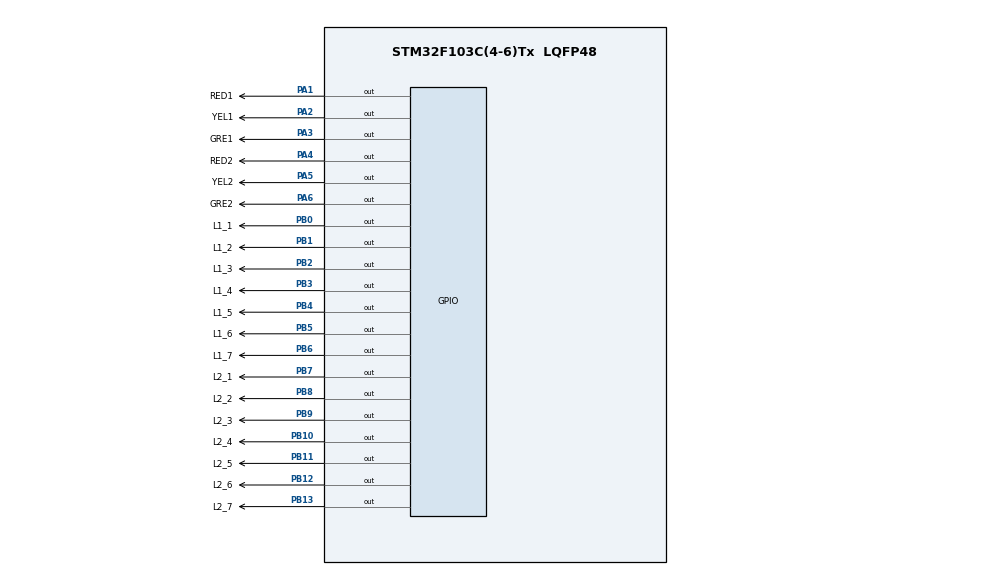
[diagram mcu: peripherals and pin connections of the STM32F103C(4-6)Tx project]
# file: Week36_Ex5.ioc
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Mcu.Family=STM32F1
PD1-OSC_OUT.Mode=HSE-External-Oscillator
PB9.GPIO_Label=L2_3
PB11.GPIO_Label=L2_5
PA6.GPIO_Label=GRE2
PB0.GPIO_Label=L1_1
PB6.GPIO_Label=L1_7
PD0-OSC_IN.Signal=RCC_OSC_IN
PB13.GPIO_Label=L2_7
PB11.Signal=GPIO_Output
PB13.Signal=GPIO_Output
VP_SYS_VS_ND.Mode=No_Debug
ProjectManager.StackSize=0x400
PD1-OSC_OUT.Signal=RCC_OSC_OUT
PB8.GPIO_Label=L2_2
ProjectManager.TargetToolchain=STM32CubeIDE
PB10.GPIO_Label=L2_4
PB6.Signal=GPIO_Output
PA1.Signal=GPIO_Output
PD0-OSC_IN.Mode=HSE-External-Oscillator
PB10.Signal=GPIO_Output
PA5.Signal=GPIO_Output
PB2.Signal=GPIO_Output
board=custom
PB12.GPIO_Label=L2_6
RCC.APB2Freq_Value=8000000
PB4.GPIO_Label=L1_5
PB1.GPIO_Label=L1_2
PA1.GPIO_Label=RED1
PB7.Signal=GPIO_Output
Mcu.Name=STM32F103C(4-6)Tx
PA2.Signal=GPIO_Output
PB7.GPIO_Label=L2_1
PB3.Signal=GPIO_Output
PA4.Signal=GPIO_Output
Mcu.Package=LQFP48
PB5.Signal=GPIO_Output
PB9.Signal=GPIO_Output
PA6.Signal=GPIO_Output
PB1.Signal=GPIO_Output
PA5.GPIO_Label=YEL2
PA2.GPIO_Label=YEL1
PB2.GPIO_Label=L1_3
ProjectManager.HeapSize=0x200
NVIC.PriorityGroup=NVIC_PRIORITYGROUP_4
PB5.GPIO_Label=L1_6
PB8.Signal=GPIO_Output
RCC.APB1Freq_Value=8000000
PB0.Signal=GPIO_Output
PA4.GPIO_Label=RED2
PB12.Signal=GPIO_Output
PB4.Signal=GPIO_Output
PA3.GPIO_Label=GRE1
PA3.Signal=GPIO_Output
PB3.GPIO_Label=L1_4

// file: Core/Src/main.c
/* USER CODE BEGIN Header */
/**
  ******************************************************************************
  * @file           : main.c
  * @brief          : Main program body
  ******************************************************************************
  * @attention
  *
  * <h2><center>&copy; Copyright (c) 2021 STMicroelectronics.
  * All rights reserved.</center></h2>
  *
  * This software component is licensed by ST under BSD 3-Clause license,
  * the "License"; You may not use this file except in compliance with the
  * License. You may obtain a copy of the License at:
  *                        opensource.org/licenses/BSD-3-Clause
  *
  ******************************************************************************
  */
/* USER CODE END Header */
#include "main.h"

void SystemClock_Config(void);
static void MX_GPIO_Init(void);
void display7SEG(int num)
{

	HAL_GPIO_WritePin(GPIOB, GPIO_PIN_0, GPIO_PIN_SET);
	HAL_GPIO_WritePin(GPIOB, GPIO_PIN_1, GPIO_PIN_SET);
	HAL_GPIO_WritePin(GPIOB, GPIO_PIN_2, GPIO_PIN_SET);
	HAL_GPIO_WritePin(GPIOB, GPIO_PIN_3, GPIO_PIN_SET);
	HAL_GPIO_WritePin(GPIOB, GPIO_PIN_4, GPIO_PIN_SET);
	HAL_GPIO_WritePin(GPIOB, GPIO_PIN_5, GPIO_PIN_SET);
	HAL_GPIO_WritePin(GPIOB, GPIO_PIN_6, GPIO_PIN_SET);
	switch (num) {
		case 0:
			HAL_GPIO_WritePin(GPIOB, GPIO_PIN_0, GPIO_PIN_RESET);
			HAL_GPIO_WritePin(GPIOB, GPIO_PIN_1, GPIO_PIN_RESET);
			HAL_GPIO_WritePin(GPIOB, GPIO_PIN_2, GPIO_PIN_RESET);
			HAL_GPIO_WritePin(GPIOB, GPIO_PIN_3, GPIO_PIN_RESET);
			HAL_GPIO_WritePin(GPIOB, GPIO_PIN_4, GPIO_PIN_RESET);
			HAL_GPIO_WritePin(GPIOB, GPIO_PIN_5, GPIO_PIN_RESET);
			break;
		case 1:
			HAL_GPIO_WritePin(GPIOB, GPIO_PIN_1, GPIO_PIN_RESET);
			HAL_GPIO_WritePin(GPIOB, GPIO_PIN_2, GPIO_PIN_RESET);
			break;
		case 2:
			HAL_GPIO_WritePin(GPIOB, GPIO_PIN_0, GPIO_PIN_RESET);
			HAL_GPIO_WritePin(GPIOB, GPIO_PIN_1, GPIO_PIN_RESET);
			HAL_GPIO_WritePin(GPIOB, GPIO_PIN_3, GPIO_PIN_RESET);
			HAL_GPIO_WritePin(GPIOB, GPIO_PIN_4, GPIO_PIN_RESET);
			HAL_GPIO_WritePin(GPIOB, GPIO_PIN_6, GPIO_PIN_RESET);
			break;
		case 3:
			HAL_GPIO_WritePin(GPIOB, GPIO_PIN_0, GPIO_PIN_RESET);
			HAL_GPIO_WritePin(GPIOB, GPIO_PIN_1, GPIO_PIN_RESET);
			HAL_GPIO_WritePin(GPIOB, GPIO_PIN_2, GPIO_PIN_RESET);
			HAL_GPIO_WritePin(GPIOB, GPIO_PIN_3, GPIO_PIN_RESET);
			HAL_GPIO_WritePin(GPIOB, GPIO_PIN_6, GPIO_PIN_RESET);
			break;
		case 4:
			HAL_GPIO_WritePin(GPIOB, GPIO_PIN_1, GPIO_PIN_RESET);
			HAL_GPIO_WritePin(GPIOB, GPIO_PIN_2, GPIO_PIN_RESET);
			HAL_GPIO_WritePin(GPIOB, GPIO_PIN_5, GPIO_PIN_RESET);
			HAL_GPIO_WritePin(GPIOB, GPIO_PIN_6, GPIO_PIN_RESET);
			break;
		case 5:
			HAL_GPIO_WritePin(GPIOB, GPIO_PIN_0, GPIO_PIN_RESET);
			HAL_GPIO_WritePin(GPIOB, GPIO_PIN_5, GPIO_PIN_RESET);
			HAL_GPIO_WritePin(GPIOB, GPIO_PIN_6, GPIO_PIN_RESET);
			HAL_GPIO_WritePin(GPIOB, GPIO_PIN_2, GPIO_PIN_RESET);
			HAL_GPIO_WritePin(GPIOB, GPIO_PIN_3, GPIO_PIN_RESET);
			break;
		case 6:
			HAL_GPIO_WritePin(GPIOB, GPIO_PIN_0, GPIO_PIN_RESET);
			HAL_GPIO_WritePin(GPIOB, GPIO_PIN_2, GPIO_PIN_RESET);
			HAL_GPIO_WritePin(GPIOB, GPIO_PIN_3, GPIO_PIN_RESET);
			HAL_GPIO_WritePin(GPIOB, GPIO_PIN_4, GPIO_PIN_RESET);
			HAL_GPIO_WritePin(GPIOB, GPIO_PIN_5, GPIO_PIN_RESET);
			HAL_GPIO_WritePin(GPIOB, GPIO_PIN_6, GPIO_PIN_RESET);
			break;
		case 7:
			HAL_GPIO_WritePin(GPIOB, GPIO_PIN_0, GPIO_PIN_RESET);
			HAL_GPIO_WritePin(GPIOB, GPIO_PIN_1, GPIO_PIN_RESET);
			HAL_GPIO_WritePin(GPIOB, GPIO_PIN_2, GPIO_PIN_RESET);
			break;
		case 8:
			HAL_GPIO_WritePin(GPIOB, GPIO_PIN_0, GPIO_PIN_RESET);
			HAL_GPIO_WritePin(GPIOB, GPIO_PIN_1, GPIO_PIN_RESET);
			HAL_GPIO_WritePin(GPIOB, GPIO_PIN_2, GPIO_PIN_RESET);
			HAL_GPIO_WritePin(GPIOB, GPIO_PIN_3, GPIO_PIN_RESET);
			HAL_GPIO_WritePin(GPIOB, GPIO_PIN_4, GPIO_PIN_RESET);
			HAL_GPIO_WritePin(GPIOB, GPIO_PIN_5, GPIO_PIN_RESET);
			HAL_GPIO_WritePin(GPIOB, GPIO_PIN_6, GPIO_PIN_RESET);

			break;
		case 9:
			HAL_GPIO_WritePin(GPIOB, GPIO_PIN_0, GPIO_PIN_RESET);
			HAL_GPIO_WritePin(GPIOB, GPIO_PIN_1, GPIO_PIN_RESET);
			HAL_GPIO_WritePin(GPIOB, GPIO_PIN_2, GPIO_PIN_RESET);
			HAL_GPIO_WritePin(GPIOB, GPIO_PIN_3, GPIO_PIN_RESET);
			HAL_GPIO_WritePin(GPIOB, GPIO_PIN_5, GPIO_PIN_RESET);
			HAL_GPIO_WritePin(GPIOB, GPIO_PIN_6, GPIO_PIN_RESET);
			break;
		default:
			HAL_GPIO_WritePin(GPIOB, GPIO_PIN_3, GPIO_PIN_SET);
			break;
		}
}

void display7SEG2(int num)
{

	HAL_GPIO_WritePin(GPIOB, GPIO_PIN_7, GPIO_PIN_SET);
	HAL_GPIO_WritePin(GPIOB, GPIO_PIN_8, GPIO_PIN_SET);
	HAL_GPIO_WritePin(GPIOB, GPIO_PIN_9, GPIO_PIN_SET);
	HAL_GPIO_WritePin(GPIOB, GPIO_PIN_10, GPIO_PIN_SET);
	HAL_GPIO_WritePin(GPIOB, GPIO_PIN_11, GPIO_PIN_SET);
	HAL_GPIO_WritePin(GPIOB, GPIO_PIN_12, GPIO_PIN_SET);
	HAL_GPIO_WritePin(GPIOB, GPIO_PIN_13, GPIO_PIN_SET);
	switch (num) {
		case 0:
			HAL_GPIO_WritePin(GPIOB, GPIO_PIN_7, GPIO_PIN_RESET);
			HAL_GPIO_WritePin(GPIOB, GPIO_PIN_8, GPIO_PIN_RESET);
			HAL_GPIO_WritePin(GPIOB, GPIO_PIN_9, GPIO_PIN_RESET);
			HAL_GPIO_WritePin(GPIOB, GPIO_PIN_10, GPIO_PIN_RESET);
			HAL_GPIO_WritePin(GPIOB, GPIO_PIN_11, GPIO_PIN_RESET);
			HAL_GPIO_WritePin(GPIOB, GPIO_PIN_12, GPIO_PIN_RESET);
			break;
		case 1:
			HAL_GPIO_WritePin(GPIOB, GPIO_PIN_8, GPIO_PIN_RESET);
			HAL_GPIO_WritePin(GPIOB, GPIO_PIN_9, GPIO_PIN_RESET);
			break;
		case 2:
			HAL_GPIO_WritePin(GPIOB, GPIO_PIN_7, GPIO_PIN_RESET);
			HAL_GPIO_WritePin(GPIOB, GPIO_PIN_8, GPIO_PIN_RESET);
			HAL_GPIO_WritePin(GPIOB, GPIO_PIN_10, GPIO_PIN_RESET);
			HAL_GPIO_WritePin(GPIOB, GPIO_PIN_11, GPIO_PIN_RESET);
			HAL_GPIO_WritePin(GPIOB, GPIO_PIN_13, GPIO_PIN_RESET);
			break;
		case 3:
			HAL_GPIO_WritePin(GPIOB, GPIO_PIN_7, GPIO_PIN_RESET);
			HAL_GPIO_WritePin(GPIOB, GPIO_PIN_8, GPIO_PIN_RESET);
			HAL_GPIO_WritePin(GPIOB, GPIO_PIN_9, GPIO_PIN_RESET);
			HAL_GPIO_WritePin(GPIOB, GPIO_PIN_10, GPIO_PIN_RESET);
			HAL_GPIO_WritePin(GPIOB, GPIO_PIN_13, GPIO_PIN_RESET);
			break;
		case 4:
			HAL_GPIO_WritePin(GPIOB, GPIO_PIN_8, GPIO_PIN_RESET);
			HAL_GPIO_WritePin(GPIOB, GPIO_PIN_9, GPIO_PIN_RESET);
			HAL_GPIO_WritePin(GPIOB, GPIO_PIN_12, GPIO_PIN_RESET);
			HAL_GPIO_WritePin(GPIOB, GPIO_PIN_13, GPIO_PIN_RESET);
			break;
		case 5:
			HAL_GPIO_WritePin(GPIOB, GPIO_PIN_7, GPIO_PIN_RESET);
			HAL_GPIO_WritePin(GPIOB, GPIO_PIN_12, GPIO_PIN_RESET);
			HAL_GPIO_WritePin(GPIOB, GPIO_PIN_13, GPIO_PIN_RESET);
			HAL_GPIO_WritePin(GPIOB, GPIO_PIN_9, GPIO_PIN_RESET);
			HAL_GPIO_WritePin(GPIOB, GPIO_PIN_10, GPIO_PIN_RESET);
			break;
		case 6:
			HAL_GPIO_WritePin(GPIOB, GPIO_PIN_7, GPIO_PIN_RESET);
			HAL_GPIO_WritePin(GPIOB, GPIO_PIN_9, GPIO_PIN_RESET);
			HAL_GPIO_WritePin(GPIOB, GPIO_PIN_10, GPIO_PIN_RESET);
			HAL_GPIO_WritePin(GPIOB, GPIO_PIN_11, GPIO_PIN_RESET);
			HAL_GPIO_WritePin(GPIOB, GPIO_PIN_12, GPIO_PIN_RESET);
			HAL_GPIO_WritePin(GPIOB, GPIO_PIN_13, GPIO_PIN_RESET);
			break;
		case 7:
			HAL_GPIO_WritePin(GPIOB, GPIO_PIN_7, GPIO_PIN_RESET);
			HAL_GPIO_WritePin(GPIOB, GPIO_PIN_8, GPIO_PIN_RESET);
			HAL_GPIO_WritePin(GPIOB, GPIO_PIN_9, GPIO_PIN_RESET);
			break;
		case 8:
			HAL_GPIO_WritePin(GPIOB, GPIO_PIN_7, GPIO_PIN_RESET);
			HAL_GPIO_WritePin(GPIOB, GPIO_PIN_9, GPIO_PIN_RESET);
			HAL_GPIO_WritePin(GPIOB, GPIO_PIN_8, GPIO_PIN_RESET);
			HAL_GPIO_WritePin(GPIOB, GPIO_PIN_10, GPIO_PIN_RESET);
			HAL_GPIO_WritePin(GPIOB, GPIO_PIN_11, GPIO_PIN_RESET);
			HAL_GPIO_WritePin(GPIOB, GPIO_PIN_12, GPIO_PIN_RESET);
			HAL_GPIO_WritePin(GPIOB, GPIO_PIN_13, GPIO_PIN_RESET);

			break;
		case 9:
			HAL_GPIO_WritePin(GPIOB, GPIO_PIN_7, GPIO_PIN_RESET);
			HAL_GPIO_WritePin(GPIOB, GPIO_PIN_8, GPIO_PIN_RESET);
			HAL_GPIO_WritePin(GPIOB, GPIO_PIN_9, GPIO_PIN_RESET);
			HAL_GPIO_WritePin(GPIOB, GPIO_PIN_10, GPIO_PIN_RESET);
			HAL_GPIO_WritePin(GPIOB, GPIO_PIN_12, GPIO_PIN_RESET);
			HAL_GPIO_WritePin(GPIOB, GPIO_PIN_13, GPIO_PIN_RESET);
			break;
		default:
			HAL_GPIO_WritePin(GPIOB, GPIO_PIN_13, GPIO_PIN_SET);
			break;
		}
}

int main(void)
{

  /* MCU Configuration--------------------------------------------------------*/

  /* Reset of all peripherals, Initializes the Flash interface and the Systick. */

  /* USER CODE BEGIN Init */
	HAL_Init();
	MX_GPIO_Init();
  /* USER CODE END Init */

  /* Configure the system clock */
  SystemClock_Config();

  /* Initialize all configured peripherals */

  /* Infinite loop */
  /* USER CODE BEGIN WHILE */
  int time_green = 3;
  int time_yellow = 2;
  int time_red = time_green + time_yellow;
  while (1)
  {
	int time1 = time_red;
	int time2 = time_green;
	HAL_GPIO_TogglePin ( GPIOA , GPIO_PIN_3 ) ; // OFF GREEN 1
	HAL_GPIO_TogglePin ( GPIOA , GPIO_PIN_2 ) ; // OFF YELLOW 1
	HAL_GPIO_TogglePin ( GPIOA , GPIO_PIN_4 ) ; // OFF RED 2
	HAL_GPIO_TogglePin ( GPIOA , GPIO_PIN_5 ) ; // OFF YELLOW 2
	for(int i=0; i<time_green;i++)
	{
		display7SEG(time1);
		display7SEG2(time2);
		time1 -= 1;
		time2 -= 1;
		HAL_Delay (1000) ;
	}
	HAL_GPIO_TogglePin ( GPIOA , GPIO_PIN_6 ) ; // OFF GREEN 2
	HAL_GPIO_TogglePin ( GPIOA , GPIO_PIN_5 ) ; // ON YELLOW 2
	time2 = time_yellow;
	for(int i=0; i<time_yellow;i++)
	{
		display7SEG(time1);
				display7SEG2(time2);
				time1 -= 1;
				time2 -= 1;
		HAL_Delay (1000) ;
	}
	HAL_GPIO_TogglePin ( GPIOA , GPIO_PIN_1 ) ; // OFF RED 1
	HAL_GPIO_TogglePin ( GPIOA , GPIO_PIN_3 ) ; // ON GREEN 1
	HAL_GPIO_TogglePin ( GPIOA , GPIO_PIN_5 ) ; // OFF YELLOW 2
	HAL_GPIO_TogglePin ( GPIOA , GPIO_PIN_4 ) ; // ON RED 2
	time1 = time_green;
	time2 = time_red;
	for(int i=0; i<time_green;i++)
		{
		display7SEG(time1);
				display7SEG2(time2);
				time1 -= 1;
				time2 -= 1;
			HAL_Delay (1000) ;
		}
	HAL_GPIO_TogglePin ( GPIOA , GPIO_PIN_3 ) ; // OFF GREEN 1
	HAL_GPIO_TogglePin ( GPIOA , GPIO_PIN_2 ) ; // ON YELLOW 1
	time1 = time_yellow;
	for(int i=0; i<time_yellow;i++)
		{
		display7SEG(time1);
				display7SEG2(time2);
				time1 -= 1;
				time2 -= 1;
			HAL_Delay (1000) ;
		}
	HAL_GPIO_TogglePin ( GPIOA , GPIO_PIN_1 ) ; // ON RED 1
	HAL_GPIO_TogglePin ( GPIOA , GPIO_PIN_3 ) ; // ON GREEN 1
	HAL_GPIO_TogglePin ( GPIOA , GPIO_PIN_5 ) ; // ON YELLOW 2
	HAL_GPIO_TogglePin ( GPIOA , GPIO_PIN_6 ) ; // ON GREEN 2
  }

}

void SystemClock_Config(void)
{
  RCC_OscInitTypeDef RCC_OscInitStruct = {0};
  RCC_ClkInitTypeDef RCC_ClkInitStruct = {0};

  /** Initializes the RCC Oscillators according to the specified parameters
  * in the RCC_OscInitTypeDef structure.
  */
  RCC_OscInitStruct.OscillatorType = RCC_OSCILLATORTYPE_HSI;
  RCC_OscInitStruct.HSIState = RCC_HSI_ON;
  RCC_OscInitStruct.HSICalibrationValue = RCC_HSICALIBRATION_DEFAULT;
  RCC_OscInitStruct.PLL.PLLState = RCC_PLL_NONE;
  if (HAL_RCC_OscConfig(&RCC_OscInitStruct) != HAL_OK)
  {
    Error_Handler();
  }
  /** Initializes the CPU, AHB and APB buses clocks
  */
  RCC_ClkInitStruct.ClockType = RCC_CLOCKTYPE_HCLK|RCC_CLOCKTYPE_SYSCLK
                              |RCC_CLOCKTYPE_PCLK1|RCC_CLOCKTYPE_PCLK2;
  RCC_ClkInitStruct.SYSCLKSource = RCC_SYSCLKSOURCE_HSI;
  RCC_ClkInitStruct.AHBCLKDivider = RCC_SYSCLK_DIV1;
  RCC_ClkInitStruct.APB1CLKDivider = RCC_HCLK_DIV1;
  RCC_ClkInitStruct.APB2CLKDivider = RCC_HCLK_DIV1;

  if (HAL_RCC_ClockConfig(&RCC_ClkInitStruct, FLASH_LATENCY_0) != HAL_OK)
  {
    Error_Handler();
  }
}

static void MX_GPIO_Init(void)
{
  GPIO_InitTypeDef GPIO_InitStruct = {0};

  /* GPIO Ports Clock Enable */
  __HAL_RCC_GPIOD_CLK_ENABLE();
  __HAL_RCC_GPIOA_CLK_ENABLE();
  __HAL_RCC_GPIOB_CLK_ENABLE();

  /*Configure GPIO pin Output Level */
  HAL_GPIO_WritePin(GPIOA, RED1_Pin|YEL1_Pin|GRE1_Pin|RED2_Pin
                          |YEL2_Pin|GRE2_Pin, GPIO_PIN_RESET);

  /*Configure GPIO pin Output Level */
  HAL_GPIO_WritePin(GPIOB, L1_1_Pin|L1_2_Pin|L1_3_Pin|L2_4_Pin
                          |L2_5_Pin|L2_6_Pin|L2_7_Pin|L1_4_Pin
                          |L1_5_Pin|L1_6_Pin|L1_7_Pin|L2_1_Pin
                          |L2_2_Pin|L2_3_Pin, GPIO_PIN_RESET);

  /*Configure GPIO pins : RED1_Pin YEL1_Pin GRE1_Pin RED2_Pin
                           YEL2_Pin GRE2_Pin */
  GPIO_InitStruct.Pin = RED1_Pin|YEL1_Pin|GRE1_Pin|RED2_Pin
                          |YEL2_Pin|GRE2_Pin;
  GPIO_InitStruct.Mode = GPIO_MODE_OUTPUT_PP;
  GPIO_InitStruct.Pull = GPIO_NOPULL;
  GPIO_InitStruct.Speed = GPIO_SPEED_FREQ_LOW;
  HAL_GPIO_Init(GPIOA, &GPIO_InitStruct);

  /*Configure GPIO pins : L1_1_Pin L1_2_Pin L1_3_Pin L2_4_Pin
                           L2_5_Pin L2_6_Pin L2_7_Pin L1_4_Pin
                           L1_5_Pin L1_6_Pin L1_7_Pin L2_1_Pin
                           L2_2_Pin L2_3_Pin */
  GPIO_InitStruct.Pin = L1_1_Pin|L1_2_Pin|L1_3_Pin|L2_4_Pin
                          |L2_5_Pin|L2_6_Pin|L2_7_Pin|L1_4_Pin
                          |L1_5_Pin|L1_6_Pin|L1_7_Pin|L2_1_Pin
                          |L2_2_Pin|L2_3_Pin;
  GPIO_InitStruct.Mode = GPIO_MODE_OUTPUT_PP;
  GPIO_InitStruct.Pull = GPIO_NOPULL;
  GPIO_InitStruct.Speed = GPIO_SPEED_FREQ_LOW;
  HAL_GPIO_Init(GPIOB, &GPIO_InitStruct);

}

void Error_Handler(void)
{
  __disable_irq();
  while (1)
  {
  }
}

/************************ (C) COPYRIGHT STMicroelectronics *****END OF FILE****/
